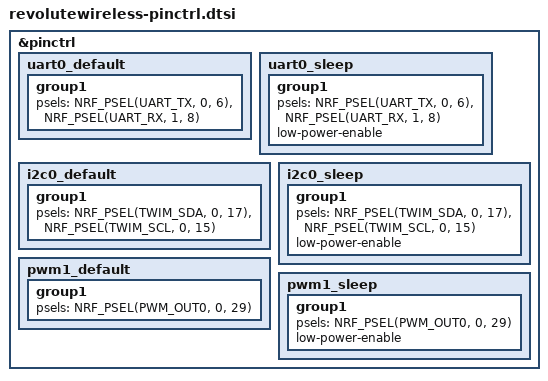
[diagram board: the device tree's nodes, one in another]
/*
 * Copyright (c) 2022 Nordic Semiconductor
 * SPDX-License-Identifier: Apache-2.0
 */

&pinctrl {
	uart0_default: uart0_default {
		group1 {
			psels = <NRF_PSEL(UART_TX, 0, 6)>,
				<NRF_PSEL(UART_RX, 1, 8)>;
		};
	};

	uart0_sleep: uart0_sleep {
		group1 {
			psels = <NRF_PSEL(UART_TX, 0, 6)>,
				<NRF_PSEL(UART_RX, 1, 8)>;
			low-power-enable;
		};
	};

	i2c0_default: i2c0_default {
		group1 {
			psels = <NRF_PSEL(TWIM_SDA, 0, 17)>,
				<NRF_PSEL(TWIM_SCL, 0, 15)>;
		};
	};

	i2c0_sleep: i2c0_sleep {
		group1 {
			psels = <NRF_PSEL(TWIM_SDA, 0, 17)>,
				<NRF_PSEL(TWIM_SCL, 0, 15)>;
			low-power-enable;
		};
	};

	pwm1_default: pwm1_default {
		group1 {
			psels = <NRF_PSEL(PWM_OUT0, 0, 29)>;

		};
	};

	pwm1_sleep: pwm1_sleep {
		group1 {
			psels = <NRF_PSEL(PWM_OUT0, 0, 29)>;
			low-power-enable;
		};
	};
};
